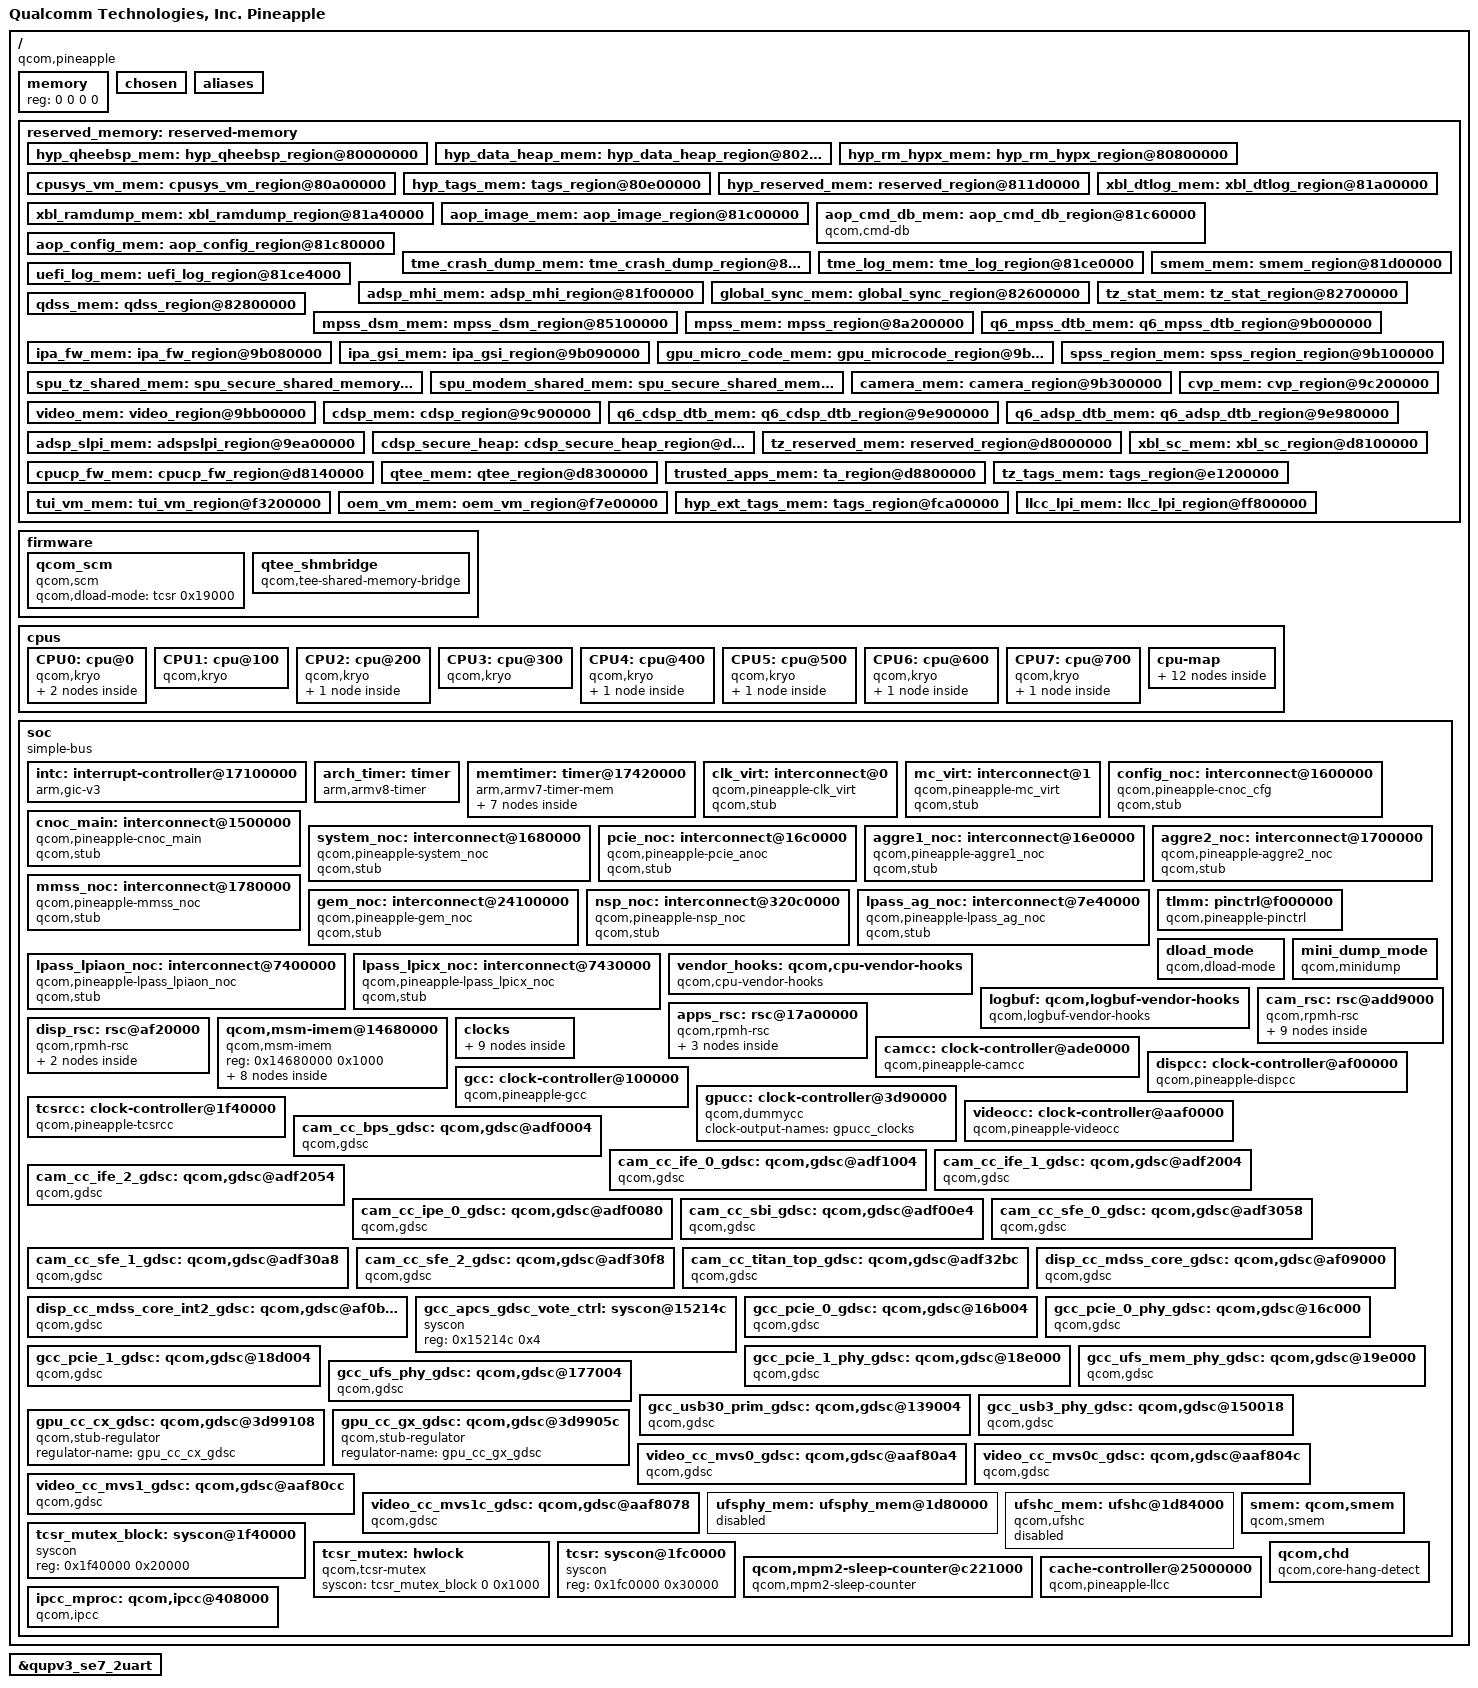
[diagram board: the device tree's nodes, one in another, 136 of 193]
#include <dt-bindings/clock/qcom,camcc-pineapple.h>
#include <dt-bindings/clock/qcom,dispcc-pineapple.h>
#include <dt-bindings/clock/qcom,gcc-pineapple.h>
#include <dt-bindings/clock/qcom,gpucc-pineapple.h>
#include <dt-bindings/clock/qcom,rpmh.h>
#include <dt-bindings/clock/qcom,tcsrcc-pineapple.h>
#include <dt-bindings/clock/qcom,videocc-pineapple.h>
#include <dt-bindings/interrupt-controller/arm-gic.h>
#include <dt-bindings/soc/qcom,rpmh-rsc.h>
#include <dt-bindings/interconnect/qcom,pineapple.h>

/ {
	model = "Qualcomm Technologies, Inc. Pineapple";
	compatible = "qcom,pineapple";
	qcom,msm-id = <557 0x10000>;
	interrupt-parent = <&intc>;

	#address-cells = <2>;
	#size-cells = <2>;
	memory { device_type = "memory"; reg = <0 0 0 0>; };


	chosen: chosen {
		bootargs = "nokaslr kpti=0 log_buf_len=256K swiotlb=0 loop.max_part=7";
		stdout-path = "/soc/qcom,qup_uart@89C000:115200n8";
	};

	aliases {
		serial0 = &qupv3_se7_2uart;
		ufshc1 = &ufshc_mem; /* Embedded UFS Slot */
	};

	reserved_memory: reserved-memory { };

	firmware: firmware { };

	cpus {
		#address-cells = <2>;
		#size-cells = <0>;

		CPU0: cpu@0 {
			device_type = "cpu";
			compatible = "qcom,kryo";
			reg = <0x0 0x0>;
			enable-method = "spin-table"; /* TODO: Update to psci */
			cpu-release-addr = <0x0 0xE3940000>;
			next-level-cache = <&L2_0>;
			L2_0: l2-cache {
			      compatible = "arm,arch-cache";
			      cache-level = <2>;
			      next-level-cache = <&L3_0>;

				L3_0: l3-cache {
					compatible = "arm,arch-cache";
					cache-level = <3>;
				};
			};
		};

		CPU1: cpu@100 {
			device_type = "cpu";
			compatible = "qcom,kryo";
			reg = <0x0 0x100>;
			enable-method = "spin-table";
			cpu-release-addr = <0x0 0xE3940000>;
			next-level-cache = <&L2_0>;
		};

		CPU2: cpu@200 {
			device_type = "cpu";
			compatible = "qcom,kryo";
			reg = <0x0 0x200>;
			enable-method = "spin-table";
			cpu-release-addr = <0x0 0xE3940000>;
			next-level-cache = <&L2_2>;
			L2_2: l2-cache {
			      compatible = "arm,arch-cache";
			      cache-level = <2>;
			      next-level-cache = <&L3_0>;
			};
		};

		CPU3: cpu@300 {
			device_type = "cpu";
			compatible = "qcom,kryo";
			reg = <0x0 0x300>;
			enable-method = "spin-table";
			cpu-release-addr = <0x0 0xE3940000>;
			next-level-cache = <&L2_2>;
		};

		CPU4: cpu@400 {
			device_type = "cpu";
			compatible = "qcom,kryo";
			reg = <0x0 0x400>;
			enable-method = "spin-table";
			cpu-release-addr = <0x0 0xE3940000>;
			next-level-cache = <&L2_4>;
			L2_4: l2-cache {
			      compatible = "arm,arch-cache";
			      cache-level = <2>;
			      next-level-cache = <&L3_0>;

			};
		};

		CPU5: cpu@500 {
			device_type = "cpu";
			compatible = "qcom,kryo";
			reg = <0x0 0x500>;
			enable-method = "spin-table"; /* TODO: Update to psci */
			cpu-release-addr = <0x0 0xE3940000>;
			next-level-cache = <&L2_5>;
			L2_5: l2-cache {
			      compatible = "arm,arch-cache";
			      cache-level = <2>;
			      next-level-cache = <&L3_0>;
			};
		};

		CPU6: cpu@600 {
			device_type = "cpu";
			compatible = "qcom,kryo";
			reg = <0x0 0x600>;
			enable-method = "spin-table"; /* TODO: Update to psci */
			cpu-release-addr = <0x0 0xE3940000>;
			next-level-cache = <&L2_6>;
			L2_6: l2-cache {
			      compatible = "arm,arch-cache";
			      cache-level = <2>;
			      next-level-cache = <&L3_0>;
			};
		};

		CPU7: cpu@700 {
			device_type = "cpu";
			compatible = "qcom,kryo";
			reg = <0x0 0x700>;
			enable-method = "spin-table"; /* TODO: Update to psci */
			cpu-release-addr = <0x0 0xE3940000>;
			next-level-cache = <&L2_7>;
			L2_7: l2-cache {
			      compatible = "arm,arch-cache";
			      cache-level = <2>;
			      next-level-cache = <&L3_0>;
			};
		};

		cpu-map {
			cluster0 {
				core0 {
					cpu = <&CPU0>;
				};
				core1 {
					cpu = <&CPU1>;
				};
			};

			cluster1 {
				core0 {
					cpu = <&CPU2>;
				};
				core1 {
					cpu = <&CPU3>;
				};
				core2 {
					cpu = <&CPU4>;
				};
			};

			cluster2 {
				core0 {
					cpu = <&CPU5>;
				};
				core1 {
					cpu = <&CPU6>;
				};
			};
			cluster3 {
				core0 {
					cpu = <&CPU7>;
				};
			};
		};
	};

	soc: soc { };
};

&soc {
	#address-cells = <1>;
	#size-cells = <1>;
	ranges = <0 0 0 0xffffffff>;
	compatible = "simple-bus";

	intc: interrupt-controller@17100000 {
		compatible = "arm,gic-v3";
		#interrupt-cells = <3>;
		interrupt-controller;
		#redistributor-regions = <1>;
		redistributor-stride = <0x0 0x40000>;
		reg = <0x17100000 0x10000>,	/* GICD */
		      <0x17180000 0x200000>;	/* GICR * 8 */
		interrupts = <GIC_PPI 9 IRQ_TYPE_LEVEL_HIGH>;
	};

	arch_timer: timer {
		compatible = "arm,armv8-timer";
		interrupts = <GIC_PPI 13 (GIC_CPU_MASK_SIMPLE(8) | IRQ_TYPE_LEVEL_LOW)>,
			     <GIC_PPI 14 (GIC_CPU_MASK_SIMPLE(8) | IRQ_TYPE_LEVEL_LOW)>,
			     <GIC_PPI 11 (GIC_CPU_MASK_SIMPLE(8) | IRQ_TYPE_LEVEL_LOW)>,
			     <GIC_PPI 12 (GIC_CPU_MASK_SIMPLE(8) | IRQ_TYPE_LEVEL_LOW)>;
		clock-frequency = <19200000>;
	};

	memtimer: timer@17420000 {
		#address-cells = <1>;
		#size-cells = <1>;
		ranges;
		compatible = "arm,armv7-timer-mem";
		reg = <0x17420000 0x1000>;
		clock-frequency = <19200000>;

		frame@17421000 {
			frame-number = <0>;
			interrupts = <GIC_SPI 8 IRQ_TYPE_LEVEL_HIGH>,
				     <GIC_SPI 6 IRQ_TYPE_LEVEL_HIGH>;
			reg = <0x17421000 0x1000>,
			      <0x17422000 0x1000>;
		};

		frame@17423000 {
			frame-number = <1>;
			interrupts = <GIC_SPI 9 IRQ_TYPE_LEVEL_HIGH>;
			reg = <0x17423000 0x1000>;
			status = "disabled";
		};

		frame@17425000 {
			frame-number = <2>;
			interrupts = <GIC_SPI 10 IRQ_TYPE_LEVEL_HIGH>;
			reg = <0x17425000 0x1000>;
			status = "disabled";
		};

		frame@17427000 {
			frame-number = <3>;
			interrupts = <GIC_SPI 11 IRQ_TYPE_LEVEL_HIGH>;
			reg = <0x17427000 0x1000>;
			status = "disabled";
		};

		frame@17429000 {
			frame-number = <4>;
			interrupts = <GIC_SPI 12 IRQ_TYPE_LEVEL_HIGH>;
			reg = <0x17429000 0x1000>;
			status = "disabled";
		};

		frame@1742b000 {
			frame-number = <5>;
			interrupts = <GIC_SPI 13 IRQ_TYPE_LEVEL_HIGH>;
			reg = <0x1742b000 0x1000>;
			status = "disabled";
		};

		frame@1742d000 {
			frame-number = <6>;
			interrupts = <GIC_SPI 14 IRQ_TYPE_LEVEL_HIGH>;
			reg = <0x1742d000 0x1000>;
			status = "disabled";
		};
	};

	clk_virt: interconnect@0 {
		compatible = "qcom,pineapple-clk_virt";
		qcom,stub;
		#interconnect-cells = <1>;
	};

	mc_virt: interconnect@1 {
		compatible = "qcom,pineapple-mc_virt";
		qcom,stub;
		#interconnect-cells = <1>;
	};

	config_noc: interconnect@1600000 {
		compatible = "qcom,pineapple-cnoc_cfg";
		qcom,stub;
		#interconnect-cells = <1>;
	};

	cnoc_main: interconnect@1500000 {
		compatible = "qcom,pineapple-cnoc_main";
		qcom,stub;
		#interconnect-cells = <1>;
	};

	system_noc: interconnect@1680000 {
		compatible = "qcom,pineapple-system_noc";
		qcom,stub;
		#interconnect-cells = <1>;
	};

	pcie_noc: interconnect@16c0000 {
		compatible = "qcom,pineapple-pcie_anoc";
		qcom,stub;
		#interconnect-cells = <1>;
	};

	aggre1_noc: interconnect@16e0000 {
		compatible = "qcom,pineapple-aggre1_noc";
		qcom,stub;
		#interconnect-cells = <1>;
	};

	aggre2_noc: interconnect@1700000 {
		compatible = "qcom,pineapple-aggre2_noc";
		qcom,stub;
		#interconnect-cells = <1>;
	};

	mmss_noc: interconnect@1780000 {
		compatible = "qcom,pineapple-mmss_noc";
		qcom,stub;
		#interconnect-cells = <1>;
	};

	gem_noc: interconnect@24100000 {
		compatible = "qcom,pineapple-gem_noc";
		qcom,stub;
		#interconnect-cells = <1>;
	};

	nsp_noc: interconnect@320c0000 {
		compatible = "qcom,pineapple-nsp_noc";
		qcom,stub;
		#interconnect-cells = <1>;
	};

	lpass_ag_noc: interconnect@7e40000 {
		compatible = "qcom,pineapple-lpass_ag_noc";
		qcom,stub;
		#interconnect-cells = <1>;
	};

	lpass_lpiaon_noc: interconnect@7400000 {
		compatible = "qcom,pineapple-lpass_lpiaon_noc";
		qcom,stub;
		#interconnect-cells = <1>;
	};

	lpass_lpicx_noc: interconnect@7430000 {
		compatible = "qcom,pineapple-lpass_lpicx_noc";
		qcom,stub;
		#interconnect-cells = <1>;
	};

	tlmm: pinctrl@f000000 {
		compatible = "qcom,pineapple-pinctrl";
		reg = <0x0F000000 0x1000000>;
		interrupts = <GIC_SPI 208 IRQ_TYPE_LEVEL_HIGH>;
		gpio-controller;
		#gpio-cells = <2>;
		interrupt-controller;
		#interrupt-cells = <2>;
	};

	dload_mode {
		compatible = "qcom,dload-mode";
	};

	mini_dump_mode {
		compatible = "qcom,minidump";
		status = "ok";
	};

	vendor_hooks: qcom,cpu-vendor-hooks {
		compatible = "qcom,cpu-vendor-hooks";
	};

	logbuf: qcom,logbuf-vendor-hooks {
		compatible = "qcom,logbuf-vendor-hooks";
	};

	apps_rsc: rsc@17a00000 {
		label = "apps_rsc";
		compatible = "qcom,rpmh-rsc";
		reg = <0x17a00000 0x10000>,
		      <0x17a10000 0x10000>,
		      <0x17a20000 0x10000>;
		reg-names = "drv-0", "drv-1", "drv-2";
		qcom,drv-count = <3>;
		interrupts = <GIC_SPI 3 IRQ_TYPE_LEVEL_HIGH>,
			     <GIC_SPI 4 IRQ_TYPE_LEVEL_HIGH>,
			     <GIC_SPI 5 IRQ_TYPE_LEVEL_HIGH>;

		apps_rsc_drv2: drv@2 {
			qcom,drv-id = <2>;
			qcom,tcs-offset = <0xd00>;
			channel@0 {
				qcom,tcs-config = <ACTIVE_TCS    3>,
						  <SLEEP_TCS     2>,
						  <WAKE_TCS      2>,
						  <CONTROL_TCS   0>,
						  <FAST_PATH_TCS 1>;
			};

			rpmhcc: clock-controller {
				compatible = "qcom,pineapple-rpmh-clk";
				#clock-cells = <1>;
			};
		};
	};

	cam_rsc: rsc@add9000 {
		label = "cam_rsc";
		compatible = "qcom,rpmh-rsc";
		reg = <0xadd4000 0x1000>,
		      <0xadd5000 0x1000>,
		      <0xadd6000 0x1000>;
		reg-names = "drv-0", "drv-1", "drv-2";
		qcom,drv-count = <3>;
		qcom,hw-channel;
		interrupts = <GIC_SPI 368 IRQ_TYPE_LEVEL_HIGH>,
			     <GIC_SPI 369 IRQ_TYPE_LEVEL_HIGH>,
			     <GIC_SPI 370 IRQ_TYPE_LEVEL_HIGH>;
		clocks = <&camcc CAM_CC_DRV_AHB_CLK>;

		cam_rsc_drv0: drv@0 {
			qcom,drv-id = <0>;
			qcom,tcs-offset = <0x520>;
			channel@0 {
				qcom,tcs-config = <ACTIVE_TCS    0>,
						  <WAKE_TCS      1>,
						  <SLEEP_TCS     1>,
						  <CONTROL_TCS   0>,
						  <FAST_PATH_TCS 0>;
			};

			channel@1 {
				qcom,tcs-config = <ACTIVE_TCS    0>,
						  <WAKE_TCS      1>,
						  <SLEEP_TCS     1>,
						  <CONTROL_TCS   0>,
						  <FAST_PATH_TCS 0>;
			};
		};

		cam_rsc_drv1: drv@1 {
			qcom,drv-id = <1>;
			qcom,tcs-offset = <0x520>;
			channel@0 {
				qcom,tcs-config = <ACTIVE_TCS    0>,
						  <WAKE_TCS      1>,
						  <SLEEP_TCS     1>,
						  <CONTROL_TCS   0>,
						  <FAST_PATH_TCS 0>;
			};

			channel@1 {
				qcom,tcs-config = <ACTIVE_TCS    0>,
						  <WAKE_TCS      1>,
						  <SLEEP_TCS     1>,
						  <CONTROL_TCS   0>,
						  <FAST_PATH_TCS 0>;
			};
		};

		cam_rsc_drv2: drv@2 {
			qcom,drv-id = <2>;
			qcom,tcs-offset = <0x520>;
			channel@0 {
				qcom,tcs-config = <ACTIVE_TCS    0>,
						  <WAKE_TCS      1>,
						  <SLEEP_TCS     1>,
						  <CONTROL_TCS   0>,
						  <FAST_PATH_TCS 0>;
			};

			channel@1 {
				qcom,tcs-config = <ACTIVE_TCS    0>,
						  <WAKE_TCS      1>,
						  <SLEEP_TCS     1>,
						  <CONTROL_TCS   0>,
						  <FAST_PATH_TCS 0>;
			};
		};
	};

	disp_rsc: rsc@af20000 {
		label = "disp_rsc";
		compatible = "qcom,rpmh-rsc";
		reg = <0xaf20000 0x10000>;
		reg-names = "drv-0";
		qcom,drv-count = <1>;
		interrupts = <GIC_SPI 129 IRQ_TYPE_LEVEL_HIGH>;
		clocks = <&dispcc DISP_CC_MDSS_RSCC_AHB_CLK>;

		disp_rsc_drv0: drv@0 {
			qcom,drv-id = <0>;
			qcom,tcs-offset = <0x1c00>;
			channel@0 {
				qcom,tcs-config = <ACTIVE_TCS    0>,
						  <SLEEP_TCS     1>,
						  <WAKE_TCS      1>,
						  <CONTROL_TCS   0>,
						  <FAST_PATH_TCS 0>;
			};
		};
	};

	qcom,msm-imem@14680000 {
		compatible = "qcom,msm-imem";
		reg = <0x14680000 0x1000>;
		ranges = <0x0 0x14680000 0x1000>;
		#address-cells = <1>;
		#size-cells = <1>;

		mem_dump_table@10 {
			compatible = "qcom,msm-imem-mem_dump_table";
			reg = <0x10 0x8>;
		};

		restart_reason@65c {
			compatible = "qcom,msm-imem-restart_reason";
			reg = <0x65c 0x4>;
		};

		dload_type@1c {
			compatible = "qcom,msm-imem-dload-type";
			reg = <0x1c 0x4>;
		};

		boot_stats@6b0 {
			compatible = "qcom,msm-imem-boot_stats";
			reg = <0x6b0 0x20>;
		};

		kaslr_offset@6d0 {
			compatible = "qcom,msm-imem-kaslr_offset";
			reg = <0x6d0 0xc>;
		};

		pil@94c {
			compatible = "qcom,pil-reloc-info";
			reg = <0x94c 0xc8>;
		};

		pil@6dc {
			compatible = "qcom,msm-imem-pil-disable-timeout";
			reg = <0x6dc 0x4>;
		};

		diag_dload@c8 {
			compatible = "qcom,msm-imem-diag-dload";
			reg = <0xc8 0xc8>;
		};
	};

	clocks {
		xo_board: xo_board {
			compatible = "fixed-clock";
			clock-frequency = <76800000>;
			clock-output-names = "xo_board";
			#clock-cells = <0>;
		};

		sleep_clk: sleep_clk {
			compatible = "fixed-clock";
			clock-frequency = <32000>;
			clock-output-names = "sleep_clk";
			#clock-cells = <0>;
		};

		pcie_0_pipe_clk: pcie_0_pipe_clk {
			compatible = "fixed-clock";
			clock-frequency = <1000>;
			clock-output-names = "pcie_0_pipe_clk";
			#clock-cells = <0>;
		};

		pcie_1_phy_aux_clk: pcie_1_phy_aux_clk {
			compatible = "fixed-clock";
			clock-frequency = <1000>;
			clock-output-names = "pcie_1_phy_aux_clk";
			#clock-cells = <0>;
		};

		pcie_1_pipe_clk: pcie_1_pipe_clk {
			compatible = "fixed-clock";
			clock-frequency = <1000>;
			clock-output-names = "pcie_1_pipe_clk";
			#clock-cells = <0>;
		};

		ufs_phy_rx_symbol_0_clk: ufs_phy_rx_symbol_0_clk {
			compatible = "fixed-clock";
			clock-frequency = <1000>;
			clock-output-names = "ufs_phy_rx_symbol_0_clk";
			#clock-cells = <0>;
		};

		ufs_phy_rx_symbol_1_clk: ufs_phy_rx_symbol_1_clk {
			compatible = "fixed-clock";
			clock-frequency = <1000>;
			clock-output-names = "ufs_phy_rx_symbol_1_clk";
			#clock-cells = <0>;
		};

		ufs_phy_tx_symbol_0_clk: ufs_phy_tx_symbol_0_clk {
			compatible = "fixed-clock";
			clock-frequency = <1000>;
			clock-output-names = "ufs_phy_tx_symbol_0_clk";
			#clock-cells = <0>;
		};

		usb3_phy_wrapper_gcc_usb30_pipe_clk: usb3_phy_wrapper_gcc_usb30_pipe_clk {
			compatible = "fixed-clock";
			clock-frequency = <1000>;
			clock-output-names = "usb3_phy_wrapper_gcc_usb30_pipe_clk";
			#clock-cells = <0>;
		};
	};

	camcc: clock-controller@ade0000 {
		compatible = "qcom,pineapple-camcc", "syscon";
		reg = <0xade0000 0x20000>;
		reg-name = "cc_base";
		vdd_mm-supply = <&VDD_MM_LEVEL>;
		vdd_mxa-supply = <&VDD_MXA_LEVEL>;
		vdd_mxc-supply = <&VDD_MXC_LEVEL>;
		clocks = <&rpmhcc RPMH_CXO_CLK>,
			 <&rpmhcc RPMH_CXO_CLK_A>,
			 <&sleep_clk>;
		clock-names = "bi_tcxo",
			      "bi_tcxo_ao",
			      "sleep_clk";
		#clock-cells = <1>;
		#reset-cells = <1>;
	};

	dispcc: clock-controller@af00000 {
		compatible = "qcom,pineapple-dispcc", "syscon";
		reg = <0xaf00000 0x20000>;
		reg-name = "cc_base";
		vdd_mm-supply = <&VDD_MM_LEVEL>;
		vdd_mxa-supply = <&VDD_MXA_LEVEL>;
		clocks = <&rpmhcc RPMH_CXO_CLK>,
			 <&sleep_clk>,
			 <&gcc GCC_DISP_AHB_CLK>;
		clock-names = "bi_tcxo",
			      "sleep_clk",
			      "iface";
		#clock-cells = <1>;
		#reset-cells = <1>;
	};

	gcc: clock-controller@100000 {
		compatible = "qcom,pineapple-gcc", "syscon";
		reg = <0x100000 0x1f4200>;
		reg-name = "cc_base";
		vdd_cx-supply = <&VDD_CX_LEVEL>;
		vdd_mxa-supply = <&VDD_MXA_LEVEL>;
		clocks = <&rpmhcc RPMH_CXO_CLK>,
			 <&pcie_0_pipe_clk>,
			 <&pcie_1_phy_aux_clk>,
			 <&pcie_1_pipe_clk>,
			 <&sleep_clk>,
			 <&ufs_phy_rx_symbol_0_clk>,
			 <&ufs_phy_rx_symbol_1_clk>,
			 <&ufs_phy_tx_symbol_0_clk>,
			 <&usb3_phy_wrapper_gcc_usb30_pipe_clk>;
		clock-names = "bi_tcxo",
			      "pcie_0_pipe_clk",
			      "pcie_1_phy_aux_clk",
			      "pcie_1_pipe_clk",
			      "sleep_clk",
			      "ufs_phy_rx_symbol_0_clk",
			      "ufs_phy_rx_symbol_1_clk",
			      "ufs_phy_tx_symbol_0_clk",
			      "usb3_phy_wrapper_gcc_usb30_pipe_clk";
		#clock-cells = <1>;
		#reset-cells = <1>;
	};

	gpucc: clock-controller@3d90000 {
		compatible = "qcom,dummycc";
		clock-output-names = "gpucc_clocks";
		#clock-cells = <1>;
		#reset-cells = <1>;
	};

	tcsrcc: clock-controller@1f40000 {
		compatible = "qcom,pineapple-tcsrcc", "syscon";
		reg = <0x1f40000 0xc0000>;
		reg-name = "cc_base";
		#clock-cells = <1>;
		#reset-cells = <1>;
	};

	videocc: clock-controller@aaf0000 {
		compatible = "qcom,pineapple-videocc", "syscon";
		reg = <0xaaf0000 0x10000>;
		reg-name = "cc_base";
		vdd_mm-supply = <&VDD_MM_LEVEL>;
		vdd_mxc-supply = <&VDD_MXC_LEVEL>;
		clocks = <&rpmhcc RPMH_CXO_CLK>,
			 <&rpmhcc RPMH_CXO_CLK_A>,
			 <&sleep_clk>;
		clock-names = "bi_tcxo",
			      "bi_tcxo_ao",
			      "sleep_clk";
		#clock-cells = <1>;
		#reset-cells = <1>;
	};

	/* CAM_CC GDSCs */
	cam_cc_bps_gdsc: qcom,gdsc@adf0004 {
		compatible = "qcom,gdsc";
		reg = <0xadf0004 0x4>;
		regulator-name = "cam_cc_bps_gdsc";
		parent-supply = <&VDD_MM_MXC_VOTER_LEVEL>;
		qcom,gds-timeout = <500>;
		qcom,retain-regs;
		qcom,support-hw-trigger;
	};

	cam_cc_ife_0_gdsc: qcom,gdsc@adf1004 {
		compatible = "qcom,gdsc";
		reg = <0xadf1004 0x4>;
		regulator-name = "cam_cc_ife_0_gdsc";
		parent-supply = <&VDD_MM_MXC_VOTER_LEVEL>;
		qcom,gds-timeout = <500>;
		qcom,retain-regs;
	};

	cam_cc_ife_1_gdsc: qcom,gdsc@adf2004 {
		compatible = "qcom,gdsc";
		reg = <0xadf2004 0x4>;
		regulator-name = "cam_cc_ife_1_gdsc";
		parent-supply = <&VDD_MM_MXC_VOTER_LEVEL>;
		qcom,gds-timeout = <500>;
		qcom,retain-regs;
	};

	cam_cc_ife_2_gdsc: qcom,gdsc@adf2054 {
		compatible = "qcom,gdsc";
		reg = <0xadf2054 0x4>;
		regulator-name = "cam_cc_ife_2_gdsc";
		parent-supply = <&VDD_MM_MXC_VOTER_LEVEL>;
		qcom,gds-timeout = <500>;
		qcom,retain-regs;
	};

	cam_cc_ipe_0_gdsc: qcom,gdsc@adf0080 {
		compatible = "qcom,gdsc";
		reg = <0xadf0080 0x4>;
		regulator-name = "cam_cc_ipe_0_gdsc";
		parent-supply = <&VDD_MM_MXC_VOTER_LEVEL>;
		qcom,gds-timeout = <500>;
		qcom,retain-regs;
		qcom,support-hw-trigger;
	};

	cam_cc_sbi_gdsc: qcom,gdsc@adf00e4 {
		compatible = "qcom,gdsc";
		reg = <0xadf00e4 0x4>;
		regulator-name = "cam_cc_sbi_gdsc";
		parent-supply = <&VDD_MM_MXC_VOTER_LEVEL>;
		qcom,gds-timeout = <500>;
		qcom,retain-regs;
	};

	cam_cc_sfe_0_gdsc: qcom,gdsc@adf3058 {
		compatible = "qcom,gdsc";
		reg = <0xadf3058 0x4>;
		regulator-name = "cam_cc_sfe_0_gdsc";
		parent-supply = <&VDD_MM_MXC_VOTER_LEVEL>;
		qcom,gds-timeout = <500>;
		qcom,retain-regs;
	};

	cam_cc_sfe_1_gdsc: qcom,gdsc@adf30a8 {
		compatible = "qcom,gdsc";
		reg = <0xadf30a8 0x4>;
		regulator-name = "cam_cc_sfe_1_gdsc";
		parent-supply = <&VDD_MM_MXC_VOTER_LEVEL>;
		qcom,gds-timeout = <500>;
		qcom,retain-regs;
	};

	cam_cc_sfe_2_gdsc: qcom,gdsc@adf30f8 {
		compatible = "qcom,gdsc";
		reg = <0xadf30f8 0x4>;
		regulator-name = "cam_cc_sfe_2_gdsc";
		parent-supply = <&VDD_MM_MXC_VOTER_LEVEL>;
		qcom,gds-timeout = <500>;
		qcom,retain-regs;
	};

	cam_cc_titan_top_gdsc: qcom,gdsc@adf32bc {
		compatible = "qcom,gdsc";
		reg = <0xadf32bc 0x4>;
		regulator-name = "cam_cc_titan_top_gdsc";
		parent-supply = <&VDD_MM_MXC_VOTER_LEVEL>;
		qcom,gds-timeout = <500>;
		qcom,retain-regs;
	};

	/* DISP_CC GDSCs */
	disp_cc_mdss_core_gdsc: qcom,gdsc@af09000 {
		compatible = "qcom,gdsc";
		reg = <0xaf09000 0x4>;
		regulator-name = "disp_cc_mdss_core_gdsc";
		clock-names = "ahb_clk";
		clocks = <&gcc GCC_DISP_AHB_CLK>;
		parent-supply = <&VDD_MM_LEVEL>;
		proxy-supply = <&disp_cc_mdss_core_gdsc>;
		qcom,gds-timeout = <1500>;
		qcom,proxy-consumer-enable;
		qcom,support-hw-trigger;
		qcom,retain-regs;
		qcom,support-cfg-gdscr;
	};

	disp_cc_mdss_core_int2_gdsc: qcom,gdsc@af0b000 {
		compatible = "qcom,gdsc";
		reg = <0xaf0b000 0x4>;
		regulator-name = "disp_cc_mdss_core_int2_gdsc";
		clock-names = "ahb_clk";
		clocks = <&gcc GCC_DISP_AHB_CLK>;
		parent-supply = <&VDD_MM_LEVEL>;
		qcom,gds-timeout = <1500>;
		qcom,support-hw-trigger;
		qcom,retain-regs;
		qcom,support-cfg-gdscr;
	};

	gcc_apcs_gdsc_vote_ctrl: syscon@15214c {
		compatible = "syscon";
		reg = <0x15214c 0x4>;
	};

	/* GCC GDSCs */
	gcc_pcie_0_gdsc: qcom,gdsc@16b004 {
		compatible = "qcom,gdsc";
		reg = <0x16b004 0x4>;
		regulator-name = "gcc_pcie_0_gdsc";
		parent-supply = <&VDD_CX_LEVEL>;
		qcom,gds-timeout = <500>;
		qcom,retain-regs;
		qcom,no-status-check-on-disable;
		qcom,collapse-vote = <&gcc_apcs_gdsc_vote_ctrl 0>;
	};

	gcc_pcie_0_phy_gdsc: qcom,gdsc@16c000 {
		compatible = "qcom,gdsc";
		reg = <0x16c000 0x4>;
		regulator-name = "gcc_pcie_0_phy_gdsc";
		parent-supply = <&VDD_CX_LEVEL>;
		qcom,gds-timeout = <500>;
		qcom,retain-regs;
		qcom,no-status-check-on-disable;
		qcom,collapse-vote = <&gcc_apcs_gdsc_vote_ctrl 3>;
	};

	gcc_pcie_1_gdsc: qcom,gdsc@18d004 {
		compatible = "qcom,gdsc";
		reg = <0x18d004 0x4>;
		regulator-name = "gcc_pcie_1_gdsc";
		parent-supply = <&VDD_CX_LEVEL>;
		qcom,gds-timeout = <500>;
		qcom,retain-regs;
		qcom,no-status-check-on-disable;
		qcom,collapse-vote = <&gcc_apcs_gdsc_vote_ctrl 1>;
	};

	gcc_pcie_1_phy_gdsc: qcom,gdsc@18e000 {
		compatible = "qcom,gdsc";
		reg = <0x18e000 0x4>;
		regulator-name = "gcc_pcie_1_phy_gdsc";
		parent-supply = <&VDD_CX_LEVEL>;
		qcom,gds-timeout = <500>;
		qcom,retain-regs;
		qcom,no-status-check-on-disable;
		qcom,collapse-vote = <&gcc_apcs_gdsc_vote_ctrl 4>;
	};

	gcc_ufs_mem_phy_gdsc: qcom,gdsc@19e000 {
		compatible = "qcom,gdsc";
		reg = <0x19e000 0x4>;
		regulator-name = "gcc_ufs_mem_phy_gdsc";
		parent-supply = <&VDD_CX_LEVEL>;
		qcom,gds-timeout = <500>;
		qcom,retain-regs;
	};

	gcc_ufs_phy_gdsc: qcom,gdsc@177004 {
		compatible = "qcom,gdsc";
		reg = <0x177004 0x4>;
		regulator-name = "gcc_ufs_phy_gdsc";
		parent-supply = <&VDD_CX_LEVEL>;
		qcom,gds-timeout = <500>;
		qcom,retain-regs;
	};

	gcc_usb30_prim_gdsc: qcom,gdsc@139004 {
		compatible = "qcom,gdsc";
		reg = <0x139004 0x4>;
		regulator-name = "gcc_usb30_prim_gdsc";
		parent-supply = <&VDD_CX_LEVEL>;
		qcom,gds-timeout = <500>;
		qcom,retain-regs;
	};

	gcc_usb3_phy_gdsc: qcom,gdsc@150018 {
		compatible = "qcom,gdsc";
		reg = <0x150018 0x4>;
		regulator-name = "gcc_usb3_phy_gdsc";
		parent-supply = <&VDD_CX_LEVEL>;
		qcom,gds-timeout = <500>;
		qcom,retain-regs;
	};

	/* GPU_CC GDSCs */
	gpu_cc_cx_gdsc: qcom,gdsc@3d99108 {
		compatible = "qcom,stub-regulator";
		regulator-name = "gpu_cc_cx_gdsc";
	};

	gpu_cc_gx_gdsc: qcom,gdsc@3d9905c {
		compatible = "qcom,stub-regulator";
		regulator-name = "gpu_cc_gx_gdsc";
	};

	/* VIDEO_CC GDSCs */
	video_cc_mvs0_gdsc: qcom,gdsc@aaf80a4 {
		compatible = "qcom,gdsc";
		reg = <0xaaf80a4 0x4>;
		regulator-name = "video_cc_mvs0_gdsc";
		parent-supply = <&VDD_MM_MXC_VOTER_LEVEL>;
		qcom,gds-timeout = <500>;
		qcom,retain-regs;
		qcom,support-hw-trigger;
	};

	video_cc_mvs0c_gdsc: qcom,gdsc@aaf804c {
		compatible = "qcom,gdsc";
		reg = <0xaaf804c 0x4>;
		regulator-name = "video_cc_mvs0c_gdsc";
		parent-supply = <&VDD_MM_MXC_VOTER_LEVEL>;
		qcom,gds-timeout = <500>;
		qcom,retain-regs;
	};

	video_cc_mvs1_gdsc: qcom,gdsc@aaf80cc {
		compatible = "qcom,gdsc";
		reg = <0xaaf80cc 0x4>;
		regulator-name = "video_cc_mvs1_gdsc";
		parent-supply = <&VDD_MM_MXC_VOTER_LEVEL>;
		qcom,gds-timeout = <500>;
		qcom,retain-regs;
		qcom,support-hw-trigger;
	};

	video_cc_mvs1c_gdsc: qcom,gdsc@aaf8078 {
		compatible = "qcom,gdsc";
		reg = <0xaaf8078 0x4>;
		regulator-name = "video_cc_mvs1c_gdsc";
		parent-supply = <&VDD_MM_MXC_VOTER_LEVEL>;
		qcom,gds-timeout = <500>;
		qcom,retain-regs;
	};

	ufsphy_mem: ufsphy_mem@1d80000 {
		reg = <0x1d80000 0x2000>;
		reg-names = "phy_mem";
		#phy-cells = <0>;

		lanes-per-direction = <2>;
		clock-names = "ref_clk_src",
			"ref_aux_clk", "qref_clk",
			"rx_sym0_mux_clk", "rx_sym1_mux_clk", "tx_sym0_mux_clk",
			"rx_sym0_phy_clk", "rx_sym1_phy_clk", "tx_sym0_phy_clk";
		clocks = <&rpmhcc RPMH_CXO_CLK>,
			<&gcc GCC_UFS_PHY_PHY_AUX_CLK>,
			<&tcsrcc TCSR_UFS_CLKREF_EN>,
			<&gcc GCC_UFS_PHY_RX_SYMBOL_0_CLK_SRC>,
			<&gcc GCC_UFS_PHY_RX_SYMBOL_1_CLK_SRC>,
			<&gcc GCC_UFS_PHY_TX_SYMBOL_0_CLK_SRC>,
			<&gcc GCC_UFS_PHY_RX_SYMBOL_0_CLK>,
			<&gcc GCC_UFS_PHY_RX_SYMBOL_1_CLK>,
			<&gcc GCC_UFS_PHY_TX_SYMBOL_0_CLK>;
		resets = <&ufshc_mem 0>;
		status = "disabled";
	};

	ufshc_mem: ufshc@1d84000 {
		compatible = "qcom,ufshc";
		reg = <0x1d84000 0x3000>;
		reg-names = "ufs_mem";
		interrupts = <GIC_SPI 265 IRQ_TYPE_LEVEL_HIGH>;
		phys = <&ufsphy_mem>;
		phy-names = "ufsphy";
		#reset-cells = <1>;

		lanes-per-direction = <2>;
		dev-ref-clk-freq = <0>; /* 19.2 MHz */
		clock-names =
			"core_clk",
			"bus_aggr_clk",
			"iface_clk",
			"core_clk_unipro",
			"core_clk_ice",
			"ref_clk",
			"tx_lane0_sync_clk",
			"rx_lane0_sync_clk",
			"rx_lane1_sync_clk";
		clocks =
			<&gcc GCC_UFS_PHY_AXI_CLK>,
			<&gcc GCC_AGGRE_UFS_PHY_AXI_CLK>,
			<&gcc GCC_UFS_PHY_AHB_CLK>,
			<&gcc GCC_UFS_PHY_UNIPRO_CORE_CLK>,
			<&gcc GCC_UFS_PHY_ICE_CORE_CLK>,
			<&rpmhcc RPMH_LN_BB_CLK3>,
			<&gcc GCC_UFS_PHY_TX_SYMBOL_0_CLK>,
			<&gcc GCC_UFS_PHY_RX_SYMBOL_0_CLK>,
			<&gcc GCC_UFS_PHY_RX_SYMBOL_1_CLK>;
		freq-table-hz =
			<100000000 403000000>,
			<0 0>,
			<0 0>,
			<100000000 403000000>,
			<100000000 403000000>,
			<0 0>,
			<0 0>,
			<0 0>,
			<0 0>;

		status = "disabled";
	};


	tcsr_mutex_block: syscon@1f40000 {
		compatible = "syscon";
		reg = <0x1f40000 0x20000>;
	};

	tcsr_mutex: hwlock {
		compatible = "qcom,tcsr-mutex";
		syscon = <&tcsr_mutex_block 0 0x1000>;
		#hwlock-cells = <1>;
	};

	smem: qcom,smem {
		compatible = "qcom,smem";
		memory-region = <&smem_mem>;
		depends-on-supply = <&tcsr_mutex>;
		hwlocks = <&tcsr_mutex 3>;
	};

	tcsr: syscon@1fc0000 {
		compatible = "syscon";
		reg = <0x1fc0000 0x30000>;
	};

	qcom,mpm2-sleep-counter@c221000 {
		compatible = "qcom,mpm2-sleep-counter";
		reg = <0xc221000 0x1000>;
		clock-frequency = <32768>;
	};

	cache-controller@25000000 {
		compatible = "qcom,pineapple-llcc", "qcom,llcc-v41";
		reg = <0x25000000 0x800000> , <0x25800000 0x200000>;
		reg-names = "llcc_base", "llcc_broadcast_base";
		interrupts = <GIC_SPI 266 IRQ_TYPE_LEVEL_HIGH>;
		cap-based-alloc-and-pwr-collapse;
	};

	ipcc_mproc: qcom,ipcc@408000 {
		compatible = "qcom,ipcc";
		reg = <0x408000 0x1000>;
		interrupts = <GIC_SPI 229 IRQ_TYPE_LEVEL_HIGH>;
		interrupt-controller;
		#interrupt-cells = <3>;
		#mbox-cells = <2>;
	};

	qcom,chd {
		compatible = "qcom,core-hang-detect";
		label = "core";
		qcom,threshold-arr = <0x17800058 0x17810058 0x17820058 0x17830058
			0x17840058 0x17850058 0x17860058 0x17870058>;
		qcom,config-arr = <0x17800060 0x17810060 0x17820060 0x17830060
			0x17840060 0x17850060 0x17860060 0x17870060>;
	};
};

&firmware {
	qcom_scm {
		compatible = "qcom,scm";
		qcom,dload-mode = <&tcsr 0x19000>;
	};

	qtee_shmbridge {
		compatible = "qcom,tee-shared-memory-bridge";
	};
};

&reserved_memory {
	#address-cells = <2>;
	#size-cells = <2>;
	ranges;

	hyp_qheebsp_mem: hyp_qheebsp_region@80000000 {
		no-map;
		reg = <0x0 0x80000000 0x0 0x200000>;
	};

	hyp_data_heap_mem: hyp_data_heap_region@80200000 {
		no-map;
		reg = <0x0 0x80200000 0x0 0x600000>;
	};

	hyp_rm_hypx_mem: hyp_rm_hypx_region@80800000 {
		no-map;
		reg = <0x0 0x80800000 0x0 0x200000>;
	};

	cpusys_vm_mem: cpusys_vm_region@80a00000 {
		no-map;
		reg = <0x0 0x80a00000 0x0 0x400000>;
	};

	hyp_tags_mem: tags_region@80e00000 {
		no-map;
		reg = <0x0 0x80e00000 0x0 0x3d0000>;
	};

	hyp_reserved_mem: reserved_region@811d0000 {
		no-map;
		reg = <0x0 0x811d0000 0x0 0x30000>;
	};

	xbl_dtlog_mem: xbl_dtlog_region@81a00000 {
		no-map;
		reg = <0x0 0x81a00000 0x0 0x40000>;
	};

	xbl_ramdump_mem: xbl_ramdump_region@81a40000 {
		no-map;
		reg = <0x0 0x81a40000 0x0 0x1c0000>;
	};

	aop_image_mem: aop_image_region@81c00000 {
		no-map;
		reg = <0x0 0x81c00000 0x0 0x60000>;
	};

	aop_cmd_db_mem: aop_cmd_db_region@81c60000 {
		compatible = "qcom,cmd-db";
		no-map;
		reg = <0x0 0x81c60000 0x0 0x20000>;
	};

	aop_config_mem: aop_config_region@81c80000 {
		no-map;
		reg = <0x0 0x81c80000 0x0 0x20000>;
	};

	tme_crash_dump_mem: tme_crash_dump_region@81ca0000 {
		no-map;
		reg = <0x0 0x81ca0000 0x0 0x40000>;
	};

	tme_log_mem: tme_log_region@81ce0000 {
		no-map;
		reg = <0x0 0x81ce0000 0x0 0x4000>;
	};

	uefi_log_mem: uefi_log_region@81ce4000 {
		no-map;
		reg = <0x0 0x81ce4000 0x0 0x10000>;
	};

	/* secdata region can be reused by apps */

	smem_mem: smem_region@81d00000 {
		no-map;
		reg = <0x0 0x81d00000 0x0 0x200000>;
	};

	adsp_mhi_mem: adsp_mhi_region@81f00000 {
		no-map;
		reg = <0x0 0x81f00000 0x0 0x20000>;
	};

	global_sync_mem: global_sync_region@82600000 {
		no-map;
		reg = <0x0 0x82600000 0x0 0x100000>;
	};

	tz_stat_mem: tz_stat_region@82700000 {
		no-map;
		reg = <0x0 0x82700000 0x0 0x100000>;
	};

	qdss_mem: qdss_region@82800000 {
		no-map;
		reg = <0x0 0x82800000 0x0 0x2000000>;
	};

	mpss_dsm_mem: mpss_dsm_region@85100000 {
		no-map;
		reg = <0x0 0x85100000 0x0 0x5100000>;
	};

	mpss_mem: mpss_region@8a200000 {
		no-map;
		reg = <0x0 0x8a200000 0x0 0x10e00000>;
	};

	q6_mpss_dtb_mem: q6_mpss_dtb_region@9b000000 {
		no-map;
		reg = <0x0 0x9b000000 0x0 0x80000>;
	};

	ipa_fw_mem: ipa_fw_region@9b080000 {
		no-map;
		reg = <0x0 0x9b080000 0x0 0x10000>;
	};

	ipa_gsi_mem: ipa_gsi_region@9b090000 {
		no-map;
		reg = <0x0 0x9b090000 0x0 0xa000>;
	};

	gpu_micro_code_mem: gpu_microcode_region@9b09a000 {
		no-map;
		reg = <0x0 0x9b09a000 0x0 0x2000>;
	};

	spss_region_mem: spss_region_region@9b100000 {
		no-map;
		reg = <0x0 0x9b100000 0x0 0x180000>;
	};

	/* First part of the "SPU secure shared memory" region */
	spu_tz_shared_mem: spu_secure_shared_memory_region@9b280000 {
		no-map;
		reg = <0x0 0x9b280000 0x0 0x60000>;
	};

	/* Second part of the "SPU secure shared memory" region */
	spu_modem_shared_mem: spu_secure_shared_memory_region@9b2e0000 {
		no-map;
		reg = <0x0 0x9b2e0000 0x0 0x20000>;
	};

	camera_mem: camera_region@9b300000 {
		no-map;
		reg = <0x0 0x9b300000 0x0 0x800000>;
	};

	video_mem: video_region@9bb00000 {
		no-map;
		reg = <0x0 0x9bb00000 0x0 0x700000>;
	};

	cvp_mem: cvp_region@9c200000 {
		no-map;
		reg = <0x0 0x9c200000 0x0 0x700000>;
	};

	cdsp_mem: cdsp_region@9c900000 {
		no-map;
		reg = <0x0 0x9c900000 0x0 0x2000000>;
	};

	q6_cdsp_dtb_mem: q6_cdsp_dtb_region@9e900000 {
		no-map;
		reg = <0x0 0x9e900000 0x0 0x80000>;
	};

	q6_adsp_dtb_mem: q6_adsp_dtb_region@9e980000 {
		no-map;
		reg = <0x0 0x9e980000 0x0 0x80000>;
	};

	adsp_slpi_mem: adspslpi_region@9ea00000 {
		no-map;
		reg = <0x0 0x9ea00000 0x0 0x4080000>;
	};

	/* uefi region can be reused by apps */

	/* Linux kernel image is loaded at 0xa8000000 */

	cdsp_secure_heap: cdsp_secure_heap_region@d3a00000 {
		no-map;
		reg = <0x0 0xd3a00000 0x0 0x4600000>;
	};

	tz_reserved_mem: reserved_region@d8000000 {
		no-map;
		reg = <0x0 0xd8000000 0x0 0x100000>;
	};

	xbl_sc_mem: xbl_sc_region@d8100000 {
		no-map;
		reg = <0x0 0xd8100000 0x0 0x40000>;
	};

	cpucp_fw_mem: cpucp_fw_region@d8140000 {
		no-map;
		reg = <0x0 0xd8140000 0x0 0x1c0000>;
	};

	qtee_mem: qtee_region@d8300000 {
		no-map;
		reg = <0x0 0xd8300000 0x0 0x500000>;
	};

	trusted_apps_mem: ta_region@d8800000 {
		no-map;
		reg = <0x0 0xd8800000 0x0 0x8a00000>;
	};

	tz_tags_mem: tags_region@e1200000 {
		no-map;
		reg = <0x0 0xe1200000 0x0 0x2710000>;
	};

	tui_vm_mem: tui_vm_region@f3200000 {
		no-map;
		reg = <0x0 0xf3200000 0x0 0x4c00000>;
	};

	oem_vm_mem: oem_vm_region@f7e00000 {
		no-map;
		reg = <0x0 0xf7e00000 0x0 0x4c00000>;
	};

	hyp_ext_tags_mem: tags_region@fca00000 {
		no-map;
		reg = <0x0 0xfca00000 0x0 0x2900000>;
	};

	llcc_lpi_mem: llcc_lpi_region@ff800000 {
		no-map;
		reg = <0x0 0xff800000 0x0 0x600000>;
	};

};

#include "ipcc-test.dtsi"
#include "pineapple-pinctrl.dtsi"
#include "pineapple-regulators.dtsi"
#include "msm-arm-smmu-pineapple.dtsi"
#include "pineapple-qupv3.dtsi"
#include "pineapple-usb.dtsi"

&qupv3_se7_2uart {
	status = "ok";
};
